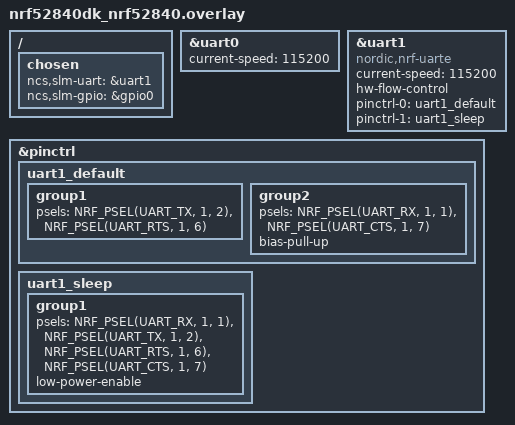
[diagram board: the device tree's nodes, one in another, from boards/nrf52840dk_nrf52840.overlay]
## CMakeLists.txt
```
#
# Copyright (c) 2023 Nordic Semiconductor ASA
#
# SPDX-License-Identifier: LicenseRef-Nordic-5-Clause
#

cmake_minimum_required(VERSION 3.20.0)

find_package(Zephyr REQUIRED HINTS $ENV{ZEPHYR_BASE})
project(slm_shell)

target_sources(app PRIVATE src/main.c)
```

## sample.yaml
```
sample:
  description: SLM shell sample
  name: slm shell
tests:
  sample.cellular.slm_shell:
    sysbuild: true
    build_only: true
    platform_allow:
      - nrf52840dk/nrf52840
      - nrf5340dk/nrf5340/cpuapp
      - nrf7002dk/nrf5340/cpuapp
      - nrf54l15dk/nrf54l15/cpuapp
    integration_platforms:
      - nrf52840dk/nrf52840
      - nrf5340dk/nrf5340/cpuapp
      - nrf7002dk/nrf5340/cpuapp
      - nrf54l15dk/nrf54l15/cpuapp
    tags:
      - ci_build
      - sysbuild
      - ci_samples_cellular
  sample.cellular.slm_shell.no_indicate_pin:
    sysbuild: true
    build_only: true
    extra_configs:
      - CONFIG_MODEM_SLM_INDICATE_PIN=-1
    platform_allow:
      - nrf52840dk/nrf52840
      - nrf5340dk/nrf5340/cpuapp
      - nrf7002dk/nrf5340/cpuapp
    integration_platforms:
      - nrf5340dk/nrf5340/cpuapp
    tags:
      - ci_build
      - sysbuild
      - ci_samples_cellular
```

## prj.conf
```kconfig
#
# Copyright (c) 2023 Nordic Semiconductor ASA
#
# SPDX-License-Identifier: LicenseRef-Nordic-5-Clause
#

CONFIG_STACK_SENTINEL=y
CONFIG_MAIN_STACK_SIZE=4096
CONFIG_HEAP_MEM_POOL_SIZE=8192
CONFIG_SYSTEM_WORKQUEUE_STACK_SIZE=2048

CONFIG_LOG=y
CONFIG_LOG_BACKEND_UART=y
CONFIG_CONSOLE=y
CONFIG_UART_CONSOLE=y
CONFIG_SHELL=y
CONFIG_SHELL_WILDCARD=n
CONFIG_SHELL_ARGC_MAX=40
CONFIG_SHELL_CMD_BUFF_SIZE=1024
CONFIG_SHELL_STACK_SIZE=2048
CONFIG_SHELL_LOG_BACKEND=n

CONFIG_SERIAL=y
CONFIG_UART_ASYNC_API=y

CONFIG_MODEM_SLM=y
CONFIG_MODEM_SLM_SHELL=y
CONFIG_MODEM_SLM_LOG_LEVEL_INF=y

CONFIG_ASSERT=y
```

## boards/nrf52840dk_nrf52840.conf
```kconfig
#
# Copyright (c) 2023 Nordic Semiconductor ASA
#
# SPDX-License-Identifier: LicenseRef-Nordic-5-Clause
#

# Configuration file for nRF52840DK.
# This file is merged with prj.conf in the application folder, and options
# set here will take precedence if they are present in both files.

CONFIG_NRFX_UARTE=y
CONFIG_UART_1_INTERRUPT_DRIVEN=n
CONFIG_UART_1_ASYNC=y
CONFIG_MODEM_SLM_POWER_PIN=11
CONFIG_MODEM_SLM_INDICATE_PIN=13
```

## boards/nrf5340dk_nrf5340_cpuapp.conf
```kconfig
#
# Copyright (c) 2023 Nordic Semiconductor ASA
#
# SPDX-License-Identifier: LicenseRef-Nordic-5-Clause
#

# Configuration file for nRF5340DK.
# This file is merged with prj.conf in the application folder, and options
# set here will take precedence if they are present in both files.

CONFIG_NRFX_UARTE=y
CONFIG_UART_2_INTERRUPT_DRIVEN=n
CONFIG_UART_2_ASYNC=y
CONFIG_MODEM_SLM_POWER_PIN=23
CONFIG_MODEM_SLM_INDICATE_PIN=28
```

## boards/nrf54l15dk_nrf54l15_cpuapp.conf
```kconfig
#
# Copyright (c) 2025 Nordic Semiconductor ASA
#
# SPDX-License-Identifier: LicenseRef-Nordic-5-Clause
#

# Configuration file for nRF54L15DK.
# This file is merged with prj.conf in the application folder, and options
# set here will take precedence if they are present in both files.

CONFIG_NRFX_UARTE21=y
CONFIG_UART_21_INTERRUPT_DRIVEN=n
# CONFIG_UART_21_NRF_HW_ASYNC=y

## P0.04 Button 3 on nRF54L15DK
CONFIG_MODEM_SLM_POWER_PIN=4
## P0.03 UART0_CST when VCOM0 HWFC is disabled in Board Configurator
#CONFIG_MODEM_SLM_INDICATE_PIN=3
```

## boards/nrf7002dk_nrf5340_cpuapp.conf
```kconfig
#
# Copyright (c) 2023 Nordic Semiconductor ASA
#
# SPDX-License-Identifier: LicenseRef-Nordic-5-Clause
#

# Configuration file for nRF7002DK.
# This file is merged with prj.conf in the application folder, and options
# set here will take precedence if they are present in both files.

CONFIG_NRFX_UARTE=y
CONFIG_UART_2_INTERRUPT_DRIVEN=n
CONFIG_UART_2_ASYNC=y
CONFIG_MODEM_SLM_POWER_PIN=30
CONFIG_MODEM_SLM_INDICATE_PIN=31
```

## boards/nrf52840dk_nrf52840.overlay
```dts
/*
 * Copyright (c) 2023 Nordic Semiconductor ASA
 *
 * SPDX-License-Identifier: LicenseRef-Nordic-5-Clause
 */

/ {
	chosen {
		ncs,slm-uart = &uart1;
		ncs,slm-gpio = &gpio0;
	};
};

/* Shell UART */
&uart0 {
	current-speed = <115200>;
	status = "okay";
};

/* SLM Shell <-> SLM UART */
&uart1 {
	compatible = "nordic,nrf-uarte";
	current-speed = <115200>;
	status = "okay";
	hw-flow-control;

	pinctrl-0 = <&uart1_default>;
	pinctrl-1 = <&uart1_sleep>;
	pinctrl-names = "default", "sleep";
};

&pinctrl {
	uart1_default: uart1_default {
		group1 {
			psels = <NRF_PSEL(UART_TX, 1, 2)>,
				<NRF_PSEL(UART_RTS, 1, 6)>;
		};

		group2 {
			psels = <NRF_PSEL(UART_RX, 1, 1)>,
				<NRF_PSEL(UART_CTS, 1, 7)>;
			bias-pull-up;
		};
	};

	uart1_sleep: uart1_sleep {
		group1 {
			psels = <NRF_PSEL(UART_RX, 1, 1)>,
				<NRF_PSEL(UART_TX, 1, 2)>,
				<NRF_PSEL(UART_RTS, 1, 6)>,
				<NRF_PSEL(UART_CTS, 1, 7)>;
			low-power-enable;
		};
	};
};
```

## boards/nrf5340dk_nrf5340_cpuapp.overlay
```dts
/*
 * Copyright (c) 2023 Nordic Semiconductor ASA
 *
 * SPDX-License-Identifier: LicenseRef-Nordic-5-Clause
 */

/ {
	chosen {
		ncs,slm-uart = &uart2;
		ncs,slm-gpio = &gpio0;
	};
};

/* Shell UART */
&uart0 {
	current-speed = <115200>;
	status = "okay";
};

/* SLM Shell <-> SLM UART */
&uart2 {
	compatible = "nordic,nrf-uarte";
	current-speed = <115200>;
	status = "okay";
	hw-flow-control;
	pinctrl-0 = <&uart2_default>;
	pinctrl-1 = <&uart2_sleep>;
	pinctrl-names = "default", "sleep";
};

&pinctrl {
	uart2_default: uart2_default {
		group1 {
			psels = <NRF_PSEL(UART_TX, 1, 4)>,
				<NRF_PSEL(UART_RTS, 1, 6)>;
		};

		group2 {
			psels = <NRF_PSEL(UART_RX, 1, 5)>,
				<NRF_PSEL(UART_CTS, 1, 7)>;
			bias-pull-up;
		};
	};

	uart2_sleep: uart2_sleep {
		group1 {
			psels = <NRF_PSEL(UART_TX, 1, 4)>,
				<NRF_PSEL(UART_RX, 1, 5)>,
				<NRF_PSEL(UART_RTS, 1, 6)>,
				<NRF_PSEL(UART_CTS, 1, 7)>;
			low-power-enable;
		};
	};
};
```

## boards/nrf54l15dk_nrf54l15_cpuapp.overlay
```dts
/*
 * Copyright (c) 2023 Nordic Semiconductor ASA
 *
 * SPDX-License-Identifier: LicenseRef-Nordic-5-Clause
 */

/ {
	chosen {
		ncs,slm-uart = &uart21;
		ncs,slm-gpio = &gpio0;
	};
};

/* Shell UART */
&uart20 {
	current-speed = <115200>;
	status = "okay";
};

/* SLM Shell <-> SLM UART */
&uart21 {
	compatible = "nordic,nrf-uarte";
	current-speed = <115200>;
	status = "okay";
	/*hw-flow-control;*/
	pinctrl-0 = <&uart21_default>;
	pinctrl-1 = <&uart21_sleep>;
	pinctrl-names = "default", "sleep";
};

/* P1.06 UART1_RST/P1.07 UART1_CTS available when VCOM1 HWFC is disabled */
&pinctrl {
	uart21_default: uart21_default {
		group1 {
			psels = <NRF_PSEL(UART_TX, 1, 11)>,
				<NRF_PSEL(UART_RTS, 1, 6)>;
		};
		group2 {
			psels = <NRF_PSEL(UART_RX, 1, 12)>,
				<NRF_PSEL(UART_CTS, 1, 7)>;
			bias-pull-up;
		};
	};

	uart21_sleep: uart21_sleep {
		group1 {
			psels = <NRF_PSEL(UART_TX, 1, 11)>,
				<NRF_PSEL(UART_RX, 1, 12)>,
				<NRF_PSEL(UART_RTS, 1, 6)>,
				<NRF_PSEL(UART_CTS, 1, 7)>;
			low-power-enable;
		};
	};
};
```

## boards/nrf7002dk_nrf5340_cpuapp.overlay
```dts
/*
 * Copyright (c) 2023 Nordic Semiconductor ASA
 *
 * SPDX-License-Identifier: LicenseRef-Nordic-5-Clause
 */

/ {
	chosen {
		ncs,slm-uart = &uart2;
		ncs,slm-gpio = &gpio0;
	};
};

/* Shell UART */
&uart0 {
	current-speed = <115200>;
	status = "okay";
};

/* SLM Shell <-> SLM UART */
&uart2 {
	compatible = "nordic,nrf-uarte";
	current-speed = <115200>;
	status = "okay";
	hw-flow-control;

	pinctrl-0 = <&uart2_default>;
	pinctrl-1 = <&uart2_sleep>;
	pinctrl-names = "default", "sleep";
};

&pinctrl {
	uart2_default: uart2_default {
		group1 {
			psels = <NRF_PSEL(UART_TX, 1, 4)>,
				<NRF_PSEL(UART_RTS, 1, 6)>;
		};

		group2 {
			psels = <NRF_PSEL(UART_RX, 1, 5)>,
				<NRF_PSEL(UART_CTS, 1, 7)>;
			bias-pull-up;
		};
	};

	uart2_sleep: uart2_sleep {
		group1 {
			psels = <NRF_PSEL(UART_TX, 1, 4)>,
				<NRF_PSEL(UART_RX, 1, 5)>,
				<NRF_PSEL(UART_RTS, 1, 6)>,
				<NRF_PSEL(UART_CTS, 1, 7)>;
			low-power-enable;
		};
	};
};
```

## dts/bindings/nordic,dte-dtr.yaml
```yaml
# Copyright (c) 2025 Nordic Semiconductor ASA
# SPDX-License-Identifier: LicenseRef-Nordic-5-Clause

description: |
    DTE side of DTR/RI UART

compatible: "nordic,dte-dtr"

properties:
  dtr-gpios:
    type: phandle-array
    description: Output. Data Terminal Ready pin
    required: true

  ri-gpios:
    type: phandle-array
    description: Input. Ring Indicator pin
    required: true
```

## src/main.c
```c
/*
 * Copyright (c) 2023 Nordic Semiconductor ASA
 *
 * SPDX-License-Identifier: LicenseRef-Nordic-5-Clause
 */

#include <stdlib.h>
#include <modem/modem_slm.h>
#include <zephyr/logging/log.h>

LOG_MODULE_REGISTER(app, CONFIG_LOG_DEFAULT_LEVEL);

SLM_MONITOR(network, "\r\n+CEREG:", cereg_mon);

static void cereg_mon(const char *notif)
{
	int status = atoi(notif + strlen("\r\n+CEREG: "));

	if (status == 1 || status == 5) {
		LOG_INF("LTE connected");
	}
}

void slm_shell_data_indication(const uint8_t *data, size_t datalen)
{
	LOG_INF("Data received (len=%d): %.*s", datalen, datalen, (const char *)data);
}

void slm_shell_ri_handler(void)
{
	LOG_INF("Ring Indicate (RI) triggered");
}

int main(void)
{
	int err;

	LOG_INF("SLM Shell starts on %s", CONFIG_BOARD);

	err = modem_slm_init(slm_shell_data_indication, true, K_MSEC(100));
	if (err) {
		LOG_ERR("Failed to initialize SLM: %d", err);
	}

	err = modem_slm_register_ri_handler(slm_shell_ri_handler);
	if (err) {
		LOG_ERR("Failed to register RI handler: %d", err);
	}

	return 0;
}
```
